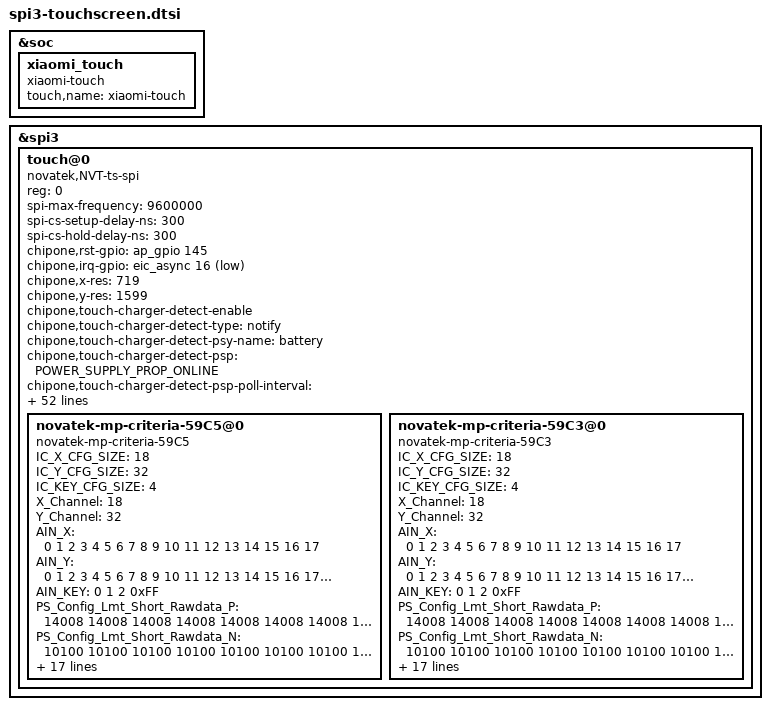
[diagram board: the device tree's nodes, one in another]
/*
 * Copyright (C) 2025 Novatek, Inc.
 *
 * $Revision$
 * $Date$
 *
 * This program is free software; you can redistribute it and/or modify
 * it under the terms of the GNU General Public License as published by
 * the Free Software Foundation; either version 2 of the License, or
 * (at your option) any later version.
 *
 * This program is distributed in the hope that it will be useful, but WITHOUT
 * ANY WARRANTY; without even the implied warranty of MERCHANTABILITY or
 * FITNESS FOR A PARTICULAR PURPOSE.  See the GNU General Public License for
 * more details.
 *
 */

&soc {
    xiaomi_touch {
        status = "okay";
        compatible = "xiaomi-touch";
        touch,name = "xiaomi-touch";
    };
};

&spi3 {
	status = "ok";

	/* Novatek device tree node */
	touch@0 {
		compatible = "novatek,NVT-ts-spi", "omnivision,tcm-spi", "chipone-tddi";
		reg = <0>; //Same as CS ID
		status = "ok";

		spi-max-frequency = <9600000>;	//4800000,9600000,15000000,19200000
		spi-cs-setup-delay-ns = <300>;
		spi-cs-hold-delay-ns = <300>;

		/* chipone_icnl9916x */
		chipone,rst-gpio = <&ap_gpio 145 0x00>;
		chipone,irq-gpio = <&eic_async 16 0x2001>;
		chipone,x-res = <719>;
		chipone,y-res = <1599>;

		/* Charger detect */
		chipone,touch-charger-detect-enable;
		chipone,touch-charger-detect-type = "notify"; /* notify, poll */
		chipone,touch-charger-detect-psy-name = "battery";
		chipone,touch-charger-detect-psp = "POWER_SUPPLY_PROP_ONLINE";
		chipone,touch-charger-detect-psp-poll-interval = <1000>;

		/* Earjack detect */
		chipone,touch-earjack-detect-enable;
		/* MTK:  /sys/bus/platform/drivers/Accdet_Driver/state,
		Sprd: /sys/kernel/headset/state
		QCOM: None, and disable it */
		chipone,touch-earjack-state-filepath = "/sys/kernel/headset/state";
		chipone,touch-earjack-poll-interval = <1000>;

		/* For tp selftest */
                chipone,test-reset-pin;
                chipone,test-int-pin;
                chipone,test-rawdata;
                chipone,test-rawdata-frames      = <1>;
                chipone,rawdata-min              = <1110>;
                chipone,rawdata-max              = <3010>;
                chipone,test-noise;
                chipone,test-noise-frames        = <50>;
                chipone,noise-max                = <120>;
                chipone,test-open;
                chipone,open-min                 = <1700>;
                chipone,test-short;
                chipone,short-min                = <1800>;
                chipone,test-compensate-cap;
                chipone,compensate-cap-min       = <1>;
                chipone,compensate-cap-max       = <127>;

		/* gesture data test */
		chipone,test-gesture-rawdata;
		chipone,test-gesture-rawdata-frames = <1>;
		chipone,gesture-rawdata-min = <100>;
		chipone,gesture-rawdata-max = <10000>;

		chipone,test-gesture-lp-rawdata;
		chipone,test-gesture-lp-rawdata-frames = <1>;
		chipone,gesture-lp-rawdata-min = <100>;
		chipone,gesture-lp-rawdata-max = <10000>;

		chipone,test-gesture-noise;
		chipone,test-gesture-noise-frames = <50>;
		chipone,gesture-noise-max = <1000>;

		chipone,test-gesture-lp-noise;
		chipone,test-gesture-lp-noise-frames = <50>;
		chipone,gesture-lp-noise-max = <1000>;

		/* td4160 */
		omnivision,bus-reg-name = "vdd";
		omnivision,pwr-reg-name = "avdd";
		omnivision,irq-on-state = <0>;
		omnivision,irq-gpio = <&eic_async 16 0x2001>;  /* IRQF_ONESHOT | IRQF_TRIGGER_LOW */
		omnivision,reset-gpio = <&ap_gpio 145 0x00>;
		omnivision,reset-on-state = <0>;
		omnivision,reset-active-ms = <20>;
		omnivision,reset-delay-ms = <200>;
		omnivision,power-delay-ms = <200>;
		omnivision,spi-mode = <3>;
		omnivision,byte-delay-us = <0>;
		omnivision,block-delay-us = <0>;
		omnivision,ubl-max-freq = <3000000>;
		omnivision,ubl-byte-delay-us = <20>;

		/* nt36528a */
		novatek,reset-gpio = <&ap_gpio 145 0x00>;
		novatek,irq-gpio = <&eic_async 16 0x2001>;

		//novatek,pen-support;
		//novatek,spi-rd-fast-addr = <0x03F310>;
		/* MP */
		novatek,mp-support-dt;

		/* for Xiaomi P25A NT36528A TM 6.9" panel module */
		novatek-mp-criteria-59C5@0 {
			#address-cells = <1>;
			#size-cells = <0>;
			compatible = "novatek-mp-criteria-59C5";

			/* MP Config */
			IC_X_CFG_SIZE = <18>;
			IC_Y_CFG_SIZE = <32>;
			IC_KEY_CFG_SIZE = <4>;
			X_Channel = <18>;
			Y_Channel = <32>;
			AIN_X = <0 1 2 3 4 5 6 7 8 9 10 11 12 13 14 15 16 17>;
			AIN_Y = <0 1 2 3 4 5 6 7 8 9 10 11 12 13 14 15 16 17 18 19 20 21 22 23 24 25 26 27 28 29 30 31>;
			AIN_KEY = <0 1 2 0xFF>;

			/* MP Criteria */
			PS_Config_Lmt_Short_Rawdata_P = <
				14008 14008 14008 14008 14008 14008 14008 14008 14008 14008 14008 14008 14008 14008 14008 14008 14008 14008
				14008 14008 14008 14008 14008 14008 14008 14008 14008 14008 14008 14008 14008 14008 14008 14008 14008 14008
				14008 14008 14008 14008 14008 14008 14008 14008 14008 14008 14008 14008 14008 14008 14008 14008 14008 14008
				14008 14008 14008 14008 14008 14008 14008 14008 14008 14008 14008 14008 14008 14008 14008 14008 14008 14008
				14008 14008 14008 14008 14008 14008 14008 14008 14008 14008 14008 14008 14008 14008 14008 14008 14008 14008
				14008 14008 14008 14008 14008 14008 14008 14008 14008 14008 14008 14008 14008 14008 14008 14008 14008 14008
				14008 14008 14008 14008 14008 14008 14008 14008 14008 14008 14008 14008 14008 14008 14008 14008 14008 14008
				14008 14008 14008 14008 14008 14008 14008 14008 14008 14008 14008 14008 14008 14008 14008 14008 14008 14008
				14008 14008 14008 14008 14008 14008 14008 14008 14008 14008 14008 14008 14008 14008 14008 14008 14008 14008
				14008 14008 14008 14008 14008 14008 14008 14008 14008 14008 14008 14008 14008 14008 14008 14008 14008 14008
				14008 14008 14008 14008 14008 14008 14008 14008 14008 14008 14008 14008 14008 14008 14008 14008 14008 14008
				14008 14008 14008 14008 14008 14008 14008 14008 14008 14008 14008 14008 14008 14008 14008 14008 14008 14008
				14008 14008 14008 14008 14008 14008 14008 14008 14008 14008 14008 14008 14008 14008 14008 14008 14008 14008
				14008 14008 14008 14008 14008 14008 14008 14008 14008 14008 14008 14008 14008 14008 14008 14008 14008 14008
				14008 14008 14008 14008 14008 14008 14008 14008 14008 14008 14008 14008 14008 14008 14008 14008 14008 14008
				14008 14008 14008 14008 14008 14008 14008 14008 14008 14008 14008 14008 14008 14008 14008 14008 14008 14008
				14008 14008 14008 14008 14008 14008 14008 14008 14008 14008 14008 14008 14008 14008 14008 14008 14008 14008
				14008 14008 14008 14008 14008 14008 14008 14008 14008 14008 14008 14008 14008 14008 14008 14008 14008 14008
				14008 14008 14008 14008 14008 14008 14008 14008 14008 14008 14008 14008 14008 14008 14008 14008 14008 14008
				14008 14008 14008 14008 14008 14008 14008 14008 14008 14008 14008 14008 14008 14008 14008 14008 14008 14008
				14008 14008 14008 14008 14008 14008 14008 14008 14008 14008 14008 14008 14008 14008 14008 14008 14008 14008
				14008 14008 14008 14008 14008 14008 14008 14008 14008 14008 14008 14008 14008 14008 14008 14008 14008 14008
				14008 14008 14008 14008 14008 14008 14008 14008 14008 14008 14008 14008 14008 14008 14008 14008 14008 14008
				14008 14008 14008 14008 14008 14008 14008 14008 14008 14008 14008 14008 14008 14008 14008 14008 14008 14008
				14008 14008 14008 14008 14008 14008 14008 14008 14008 14008 14008 14008 14008 14008 14008 14008 14008 14008
				14008 14008 14008 14008 14008 14008 14008 14008 14008 14008 14008 14008 14008 14008 14008 14008 14008 14008
				14008 14008 14008 14008 14008 14008 14008 14008 14008 14008 14008 14008 14008 14008 14008 14008 14008 14008
				14008 14008 14008 14008 14008 14008 14008 14008 14008 14008 14008 14008 14008 14008 14008 14008 14008 14008
				14008 14008 14008 14008 14008 14008 14008 14008 14008 14008 14008 14008 14008 14008 14008 14008 14008 14008
				14008 14008 14008 14008 14008 14008 14008 14008 14008 14008 14008 14008 14008 14008 14008 14008 14008 14008
				14008 14008 14008 14008 14008 14008 14008 14008 14008 14008 14008 14008 14008 14008 14008 14008 14008 14008
				14008 14008 14008 14008 14008 14008 14008 14008 14008 14008 14008 14008 14008 14008 14008 14008 14008 14008
				14008 14008 14008>;

			PS_Config_Lmt_Short_Rawdata_N = <
				10100 10100 10100 10100 10100 10100 10100 10100 10100 10100 10100 10100 10100 10100 10100 10100 10100 10100
				10100 10100 10100 10100 10100 10100 10100 10100 10100 10100 10100 10100 10100 10100 10100 10100 10100 10100
				10100 10100 10100 10100 10100 10100 10100 10100 10100 10100 10100 10100 10100 10100 10100 10100 10100 10100
				10100 10100 10100 10100 10100 10100 10100 10100 10100 10100 10100 10100 10100 10100 10100 10100 10100 10100
				10100 10100 10100 10100 10100 10100 10100 10100 10100 10100 10100 10100 10100 10100 10100 10100 10100 10100
				10100 10100 10100 10100 10100 10100 10100 10100 10100 10100 10100 10100 10100 10100 10100 10100 10100 10100
				10100 10100 10100 10100 10100 10100 10100 10100 10100 10100 10100 10100 10100 10100 10100 10100 10100 10100
				10100 10100 10100 10100 10100 10100 10100 10100 10100 10100 10100 10100 10100 10100 10100 10100 10100 10100
				10100 10100 10100 10100 10100 10100 10100 10100 10100 10100 10100 10100 10100 10100 10100 10100 10100 10100
				10100 10100 10100 10100 10100 10100 10100 10100 10100 10100 10100 10100 10100 10100 10100 10100 10100 10100
				10100 10100 10100 10100 10100 10100 10100 10100 10100 10100 10100 10100 10100 10100 10100 10100 10100 10100
				10100 10100 10100 10100 10100 10100 10100 10100 10100 10100 10100 10100 10100 10100 10100 10100 10100 10100
				10100 10100 10100 10100 10100 10100 10100 10100 10100 10100 10100 10100 10100 10100 10100 10100 10100 10100
				10100 10100 10100 10100 10100 10100 10100 10100 10100 10100 10100 10100 10100 10100 10100 10100 10100 10100
				10100 10100 10100 10100 10100 10100 10100 10100 10100 10100 10100 10100 10100 10100 10100 10100 10100 10100
				10100 10100 10100 10100 10100 10100 10100 10100 10100 10100 10100 10100 10100 10100 10100 10100 10100 10100
				10100 10100 10100 10100 10100 10100 10100 10100 10100 10100 10100 10100 10100 10100 10100 10100 10100 10100
				10100 10100 10100 10100 10100 10100 10100 10100 10100 10100 10100 10100 10100 10100 10100 10100 10100 10100
				10100 10100 10100 10100 10100 10100 10100 10100 10100 10100 10100 10100 10100 10100 10100 10100 10100 10100
				10100 10100 10100 10100 10100 10100 10100 10100 10100 10100 10100 10100 10100 10100 10100 10100 10100 10100
				10100 10100 10100 10100 10100 10100 10100 10100 10100 10100 10100 10100 10100 10100 10100 10100 10100 10100
				10100 10100 10100 10100 10100 10100 10100 10100 10100 10100 10100 10100 10100 10100 10100 10100 10100 10100
				10100 10100 10100 10100 10100 10100 10100 10100 10100 10100 10100 10100 10100 10100 10100 10100 10100 10100
				10100 10100 10100 10100 10100 10100 10100 10100 10100 10100 10100 10100 10100 10100 10100 10100 10100 10100
				10100 10100 10100 10100 10100 10100 10100 10100 10100 10100 10100 10100 10100 10100 10100 10100 10100 10100
				10100 10100 10100 10100 10100 10100 10100 10100 10100 10100 10100 10100 10100 10100 10100 10100 10100 10100
				10100 10100 10100 10100 10100 10100 10100 10100 10100 10100 10100 10100 10100 10100 10100 10100 10100 10100
				10100 10100 10100 10100 10100 10100 10100 10100 10100 10100 10100 10100 10100 10100 10100 10100 10100 10100
				10100 10100 10100 10100 10100 10100 10100 10100 10100 10100 10100 10100 10100 10100 10100 10100 10100 10100
				10100 10100 10100 10100 10100 10100 10100 10100 10100 10100 10100 10100 10100 10100 10100 10100 10100 10100
				10100 10100 10100 10100 10100 10100 10100 10100 10100 10100 10100 10100 10100 10100 10100 10100 10100 10100
				10100 10100 10100 10100 10100 10100 10100 10100 10100 10100 10100 10100 10100 10100 10100 10100 10100 10100
				10100 10100 10100>;

			PS_Config_Lmt_Open_Rawdata_P = <
				65535 3126 3087 3034 2962 2897 2852 2744 65535 65535 2729 2814 2859 2899 2937 2974 3006 65535
				3247 3228 3191 3153 3083 3013 2958 2901 2848 2748 2786 2827 2874 2922 2967 2988 3018 3091
				3289 3293 3238 3181 3112 3044 2986 2932 2887 2801 2834 2881 2925 2975 3021 3056 3102 3161
				3219 3240 3185 3123 3053 2986 2926 2874 2827 2792 2828 2870 2918 2968 3016 3055 3104 3163
				3329 3360 3304 3242 3175 3105 3042 2993 2943 2818 2848 2895 2941 2996 3041 3079 3128 3178
				3349 3388 3333 3270 3199 3130 3074 3020 2975 2845 2877 2925 2972 3024 3072 3109 3161 3214
				3303 3269 3199 3150 3074 3003 2958 2898 2846 2947 2993 3048 3084 3137 3191 3221 3287 3209
				3350 3310 3245 3191 3114 3044 2997 2941 2885 2957 3004 3051 3090 3146 3198 3230 3289 3228
				3413 3368 3303 3249 3175 3105 3056 2999 2943 2988 3032 3084 3118 3177 3231 3262 3324 3277
				3468 3420 3357 3298 3221 3150 3102 3044 2988 3003 3049 3101 3136 3192 3245 3280 3338 3304
				3499 3448 3380 3326 3248 3174 3129 3072 3016 3156 3203 3252 3297 3354 3405 3438 3501 3473
				3534 3475 3409 3354 3276 3203 3154 3090 3038 3137 3182 3235 3279 3336 3389 3427 3487 3476
				3588 3532 3466 3413 3333 3256 3210 3146 3093 3135 3186 3231 3276 3336 3385 3420 3482 3483
				3661 3606 3534 3479 3402 3326 3275 3214 3160 3182 3233 3279 3325 3384 3431 3466 3528 3535
				3703 3644 3577 3522 3451 3374 3322 3262 3207 3273 3317 3373 3412 3475 3527 3556 3619 3644
				3758 3696 3630 3569 3489 3416 3363 3304 3245 3242 3286 3340 3384 3441 3496 3534 3595 3630
				3795 3732 3668 3606 3529 3454 3401 3340 3283 3328 3370 3422 3468 3528 3583 3615 3674 3721
				3833 3766 3707 3643 3563 3489 3438 3373 3318 3336 3377 3436 3473 3534 3585 3620 3674 3721
				3872 3809 3748 3689 3606 3529 3482 3413 3366 3371 3419 3462 3514 3569 3620 3664 3718 3769
				3907 3840 3776 3717 3634 3559 3501 3440 3385 3402 3447 3494 3545 3599 3654 3697 3751 3814
				4015 3949 3884 3825 3742 3662 3609 3546 3493 3431 3480 3531 3578 3633 3689 3725 3781 3849
				4057 3993 3933 3868 3791 3711 3657 3594 3534 3543 3592 3644 3695 3753 3807 3850 3902 3962
				4092 4021 3963 3902 3826 3752 3693 3634 3569 3613 3660 3714 3762 3821 3877 3913 3965 4031
				4122 4053 3996 3927 3849 3773 3714 3654 3597 3599 3644 3699 3746 3804 3863 3906 3961 4021
				4236 4161 4106 4043 3959 3881 3830 3770 3709 3723 3769 3821 3868 3928 3979 4022 4074 4140
				4224 4157 4103 4038 3954 3879 3825 3763 3707 3749 3795 3850 3898 3961 4015 4063 4112 4173
				4281 4222 4162 4101 4022 3944 3886 3822 3765 3774 3828 3877 3928 3984 4042 4087 4140 4204
				4336 4274 4217 4157 4071 4003 3944 3881 3823 3833 3878 3931 3983 4038 4095 4136 4185 4250
				3871 4334 4273 4213 4133 4054 3994 3931 3872 3865 3916 3970 4019 4084 4141 4183 4236 3815
				3924 4407 4350 4278 4203 4124 4061 3994 3941 3884 3927 3979 4029 4085 4138 4186 4236 3802
				3991 4577 4515 4444 4361 4278 4214 4154 4098 3987 4033 4085 4140 4203 4260 4311 4365 3840
				4017 4263 4536 4473 4383 4301 4239 4172 4116 3994 4045 4098 4150 4213 4274 4316 4066 3868
				5120 5120 5120>;

			PS_Config_Lmt_Open_Rawdata_N = <
				(-65535) 1340 1323 1300 1270 1241 1222 1176 (-65535) (-65535) 1169 1206 1225 1243 1259 1274 1288 (-65535)
				1391 1384 1367 1351 1321 1291 1268 1243 1220 1178 1194 1211 1232 1252 1271 1280 1294 1325
				1409 1411 1388 1363 1334 1304 1280 1256 1237 1201 1214 1235 1253 1275 1295 1310 1330 1355
				1379 1388 1365 1339 1309 1280 1254 1232 1211 1196 1212 1230 1250 1272 1292 1309 1330 1355
				1427 1440 1416 1390 1361 1331 1304 1283 1261 1208 1220 1241 1261 1284 1303 1319 1340 1362
				1435 1452 1429 1402 1371 1342 1318 1294 1275 1219 1233 1253 1274 1296 1316 1333 1355 1378
				1415 1401 1371 1350 1318 1287 1268 1242 1220 1263 1283 1306 1322 1345 1367 1381 1409 1375
				1436 1418 1391 1367 1334 1304 1285 1261 1237 1267 1288 1307 1324 1348 1370 1384 1409 1384
				1463 1444 1415 1393 1361 1331 1310 1285 1261 1280 1300 1322 1336 1361 1385 1398 1424 1405
				1486 1466 1439 1414 1381 1350 1330 1304 1280 1287 1307 1329 1344 1368 1391 1406 1430 1416
				1499 1478 1448 1426 1392 1360 1341 1316 1292 1352 1373 1394 1413 1438 1459 1474 1501 1489
				1514 1489 1461 1438 1404 1373 1352 1324 1302 1345 1364 1387 1405 1430 1453 1469 1495 1490
				1538 1514 1486 1463 1429 1396 1376 1348 1325 1343 1366 1385 1404 1430 1451 1466 1492 1493
				1569 1546 1514 1491 1458 1426 1403 1378 1354 1364 1385 1405 1425 1450 1471 1486 1512 1515
				1587 1562 1533 1510 1479 1446 1424 1398 1375 1403 1421 1445 1462 1489 1511 1524 1551 1562
				1610 1584 1556 1529 1495 1464 1441 1416 1391 1390 1408 1432 1450 1475 1498 1514 1541 1556
				1627 1600 1572 1546 1513 1480 1457 1432 1407 1426 1444 1466 1486 1512 1535 1549 1574 1595
				1643 1614 1589 1561 1527 1495 1474 1445 1422 1430 1447 1472 1489 1514 1537 1552 1574 1595
				1660 1633 1606 1581 1546 1513 1492 1463 1442 1445 1465 1484 1506 1529 1552 1570 1594 1615
				1675 1646 1618 1593 1558 1525 1501 1474 1451 1458 1477 1498 1519 1543 1566 1585 1607 1634
				1721 1693 1664 1639 1604 1570 1547 1520 1497 1471 1492 1513 1534 1557 1581 1597 1621 1649
				1739 1711 1685 1658 1625 1591 1567 1540 1514 1519 1540 1562 1583 1609 1631 1650 1672 1698
				1754 1723 1699 1672 1640 1608 1583 1558 1529 1549 1568 1592 1612 1637 1661 1677 1699 1727
				1766 1737 1712 1683 1649 1617 1592 1566 1541 1543 1562 1585 1606 1630 1655 1674 1697 1723
				1816 1783 1760 1733 1697 1663 1642 1616 1589 1595 1615 1637 1658 1684 1705 1724 1746 1774
				1810 1781 1759 1730 1694 1663 1639 1613 1589 1607 1627 1650 1670 1697 1721 1741 1762 1789
				1835 1810 1784 1757 1724 1690 1666 1638 1613 1618 1640 1661 1684 1708 1732 1751 1774 1802
				1858 1832 1807 1781 1745 1715 1690 1663 1639 1643 1662 1685 1707 1730 1755 1772 1793 1822
				1659 1858 1831 1805 1771 1738 1712 1685 1660 1657 1678 1702 1723 1750 1775 1793 1816 1635
				1682 1889 1864 1834 1801 1768 1741 1712 1689 1664 1683 1705 1727 1751 1774 1794 1816 1630
				1711 1961 1935 1904 1869 1834 1806 1780 1756 1709 1729 1751 1774 1801 1826 1847 1871 1646
				1721 1827 1944 1917 1879 1843 1817 1788 1764 1712 1733 1756 1778 1805 1832 1850 1742 1658
				(-511) (-511) (-511)>;

			PS_Config_Lmt_FW_Rawdata_P = <
				65535 1152 1130 1123 1124 1141 1088 1120 65535 65535 1098 1113 1127 1120 1106 1102 1117 65535
				1119 1114 1106 1109 1107 1131 1110 1116 1123 1123 1140 1086 1128 1109 1106 1121 1119 1116
				1119 1116 1117 1105 1127 1126 1105 1128 1103 1110 1106 1131 1093 1140 1107 1098 1130 1124
				1098 1134 1116 1098 1140 1107 1134 1113 1088 1144 1100 1126 1110 1089 1133 1133 1113 1102
				1089 1138 1116 1091 1131 1138 1110 1121 1114 1128 1130 1106 1123 1120 1107 1113 1147 1117
				1133 1117 1133 1131 1110 1102 1117 1116 1144 1128 1128 1110 1110 1109 1124 1127 1124 1100
				1109 1120 1103 1113 1154 1102 1089 1151 1086 1106 1096 1112 1145 1085 1134 1142 1137 1088
				1120 1127 1110 1113 1116 1117 1099 1123 1114 1110 1120 1120 1119 1091 1123 1116 1142 1099
				1110 1142 1117 1138 1100 1135 1119 1084 1137 1095 1148 1070 1113 1145 1082 1120 1086 1137
				1114 1113 1124 1138 1119 1112 1130 1114 1114 1112 1113 1106 1124 1128 1093 1126 1074 1137
				1107 1112 1102 1103 1117 1120 1119 1098 1106 1119 1110 1116 1130 1103 1114 1117 1126 1117
				1113 1144 1112 1124 1102 1127 1121 1112 1126 1123 1096 1131 1126 1121 1120 1123 1133 1119
				1107 1127 1113 1131 1130 1106 1086 1123 1119 1092 1141 1121 1093 1124 1124 1114 1116 1128
				1116 1152 1119 1138 1121 1114 1123 1126 1127 1113 1126 1116 1105 1128 1151 1091 1134 1107
				1054 1121 1140 1128 1103 1086 1117 1149 1106 1147 1085 1098 1131 1145 1100 1123 1131 1112
				1105 1135 1112 1131 1138 1113 1086 1137 1116 1127 1144 1106 1114 1112 1126 1137 1113 1119
				1169 1065 1131 1077 1147 1121 1078 1135 1127 1119 1123 1113 1106 1106 1140 1105 1102 1105
				1116 1116 1112 1121 1123 1117 1109 1119 1113 1133 1113 1116 1137 1114 1123 1127 1113 1123
				1121 1127 1123 1092 1135 1140 1119 1110 1140 1120 1107 1107 1131 1126 1116 1106 1121 1106
				1099 1134 1100 1098 1142 1138 1106 1095 1151 1109 1134 1137 1114 1099 1110 1126 1126 1120
				1107 1113 1114 1126 1128 1121 1109 1123 1137 1138 1116 1114 1134 1098 1113 1123 1102 1133
				1126 1135 1130 1102 1107 1138 1130 1106 1119 1105 1152 1120 1099 1099 1133 1147 1098 1127
				1096 1144 1119 1099 1099 1142 1116 1114 1095 1121 1130 1113 1102 1128 1124 1123 1093 1112
				1142 1130 1151 1117 1096 1107 1142 1137 1098 1134 1114 1133 1106 1113 1123 1145 1106 1155
				1098 1144 1112 1098 1103 1141 1140 1120 1092 1117 1114 1109 1113 1138 1134 1095 1098 1119
				1110 1128 1140 1112 1075 1110 1163 1133 1110 1112 1105 1105 1124 1145 1105 1114 1135 1109
				1082 1119 1063 1078 1126 1141 1133 1103 1110 1126 1119 1103 1113 1138 1110 1100 1114 1105
				1117 1114 1107 1112 1128 1120 1121 1112 1116 1127 1144 1135 1092 1079 1123 1127 1144 1120
				1135 1103 1130 1121 1127 1119 1110 1089 1093 1144 1133 1110 1107 1105 1126 1128 1126 1098
				1117 1113 1121 1124 1102 1102 1099 1100 1100 1107 1112 1124 1131 1124 1107 1103 1103 1110
				1141 1114 1130 1137 1121 1112 1091 1081 1086 1137 1141 1106 1100 1095 1123 1126 1137 1127
				1102 1137 1093 1095 1106 1114 1135 1105 1121 1116 1112 1137 1149 1142 1130 1121 1110 1120
				3840 3840 3840>;

			PS_Config_Lmt_FW_Rawdata_N = <
				(-65535) 494 484 481 482 489 466 480 (-65535) (-65535) 470 477 483 480 474 472 479 (-65535)
				479 478 474 475 475 485 476 478 481 481 488 466 484 475 474 481 479 478
				479 478 479 473 483 482 473 484 473 476 474 485 469 488 475 470 484 482
				470 486 478 470 488 475 486 477 466 490 472 482 476 467 485 485 477 472
				467 488 478 467 485 488 476 481 478 484 484 474 481 480 475 477 491 479
				485 479 485 485 476 472 479 478 490 484 484 476 476 475 482 483 482 472
				475 480 473 477 494 472 467 493 466 474 470 476 491 465 486 490 487 466
				480 483 476 477 478 479 471 481 478 476 480 480 479 467 481 478 490 471
				476 490 479 488 472 487 479 464 487 469 492 458 477 491 464 480 466 487
				478 477 482 488 479 476 484 478 478 476 477 474 482 484 469 482 460 487
				475 476 472 473 479 480 479 470 474 479 476 478 484 473 478 479 482 479
				477 490 476 482 472 483 481 476 482 481 470 485 482 481 480 481 485 479
				475 483 477 485 484 474 466 481 479 468 489 481 469 482 482 478 478 484
				478 494 479 488 481 478 481 482 483 477 482 478 473 484 493 467 486 475
				452 481 488 484 473 466 479 493 474 491 465 470 485 491 472 481 485 476
				473 487 476 485 488 477 466 487 478 483 490 474 478 476 482 487 477 479
				501 457 485 461 491 481 462 487 483 479 481 477 474 474 488 473 472 473
				478 478 476 481 481 479 475 479 477 485 477 478 487 478 481 483 477 481
				481 483 481 468 487 488 479 476 488 480 475 475 485 482 478 474 481 474
				471 486 472 470 490 488 474 469 493 475 486 487 478 471 476 482 482 480
				475 477 478 482 484 481 475 481 487 488 478 478 486 470 477 481 472 485
				482 487 484 472 475 488 484 474 479 473 494 480 471 471 485 491 470 483
				470 490 479 471 471 490 478 478 469 481 484 477 472 484 482 481 469 476
				490 484 493 479 470 475 490 487 470 486 478 485 474 477 481 491 474 495
				470 490 476 470 473 489 488 480 468 479 478 475 477 488 486 469 470 479
				476 484 488 476 461 476 499 485 476 476 473 473 482 491 473 478 487 475
				464 479 455 462 482 489 485 473 476 482 479 473 477 488 476 472 478 473
				479 478 475 476 484 480 481 476 478 483 490 487 468 463 481 483 490 480
				487 473 484 481 483 479 476 467 469 490 485 476 475 473 482 484 482 470
				479 477 481 482 472 472 471 472 472 475 476 482 485 482 475 473 473 476
				489 478 484 487 481 476 467 463 466 487 489 474 472 469 481 482 487 483
				472 487 469 469 474 478 487 473 481 478 476 487 493 490 484 481 476 480
				240 240 240>;

			PS_Config_Lmt_FW_CC_P = <
				65535 32 32 32 30 30 30 29 65535 65535 29 29 30 30 32 32 32 65535
				33 32 32 30 30 30 29 29 29 29 29 29 30 30 32 32 32 33
				33 33 32 32 32 30 30 29 29 29 29 29 30 30 32 32 32 33
				33 32 32 32 30 30 30 29 29 29 29 30 30 32 32 32 33 33
				33 33 32 32 32 30 30 30 29 29 30 30 30 32 32 32 33 33
				33 33 32 32 32 32 30 30 30 29 30 30 30 32 32 32 33 34
				34 33 33 32 30 30 30 29 29 29 29 30 30 32 32 33 33 34
				34 33 33 32 32 30 30 29 29 29 30 30 30 32 32 33 33 34
				34 33 33 32 32 30 30 30 29 29 30 30 30 32 32 33 33 34
				34 33 33 32 32 30 30 30 29 29 30 30 30 32 32 33 33 34
				34 34 33 32 32 32 30 30 30 30 30 32 32 32 33 33 34 34
				34 33 33 32 32 30 30 30 29 30 30 30 32 32 32 33 34 34
				34 33 33 32 32 32 32 30 30 30 30 32 32 32 33 33 34 34
				34 33 33 32 32 32 30 30 30 30 30 32 32 32 32 33 33 34
				34 34 33 33 32 32 32 30 30 30 30 32 32 32 33 33 33 34
				34 34 33 33 32 32 32 32 30 30 32 32 32 33 33 33 34 34
				34 34 33 33 33 32 32 32 30 30 32 32 32 33 33 33 34 34
				36 34 33 33 33 32 32 32 30 32 32 32 32 33 33 33 34 34
				36 34 34 33 33 33 33 32 32 32 32 33 33 33 33 34 34 36
				36 34 34 34 33 33 33 32 32 32 32 33 33 33 34 34 34 36
				36 36 34 34 34 33 33 33 32 33 33 33 33 34 34 34 34 36
				36 36 34 34 34 33 33 33 33 33 33 33 34 34 34 34 36 36
				37 36 36 36 36 34 34 34 34 33 34 34 34 34 36 36 36 37
				36 36 36 34 34 34 34 33 33 33 34 34 34 34 36 36 36 37
				37 36 36 36 36 34 34 34 34 34 34 34 34 36 36 36 36 37
				37 36 36 36 36 34 34 34 34 34 34 34 34 34 36 36 36 37
				37 37 37 36 36 36 36 36 34 34 34 36 36 36 36 36 37 37
				37 37 36 36 36 36 36 34 34 34 34 36 36 36 36 36 37 37
				39 37 37 37 37 36 36 36 36 36 36 36 36 36 36 36 37 39
				39 37 37 37 37 36 36 36 36 36 36 36 36 36 37 37 37 39
				39 37 37 37 36 36 36 36 36 36 36 36 36 36 37 37 37 39
				39 37 37 37 37 37 36 36 36 36 36 36 36 36 36 37 37 39
				314 314 314>;

			PS_Config_Lmt_FW_CC_N = <
				(-65535) 14 14 14 14 14 14 13 (-65535) (-65535) 13 13 14 14 14 14 14 (-65535)
				15 14 14 14 14 14 13 13 13 13 13 13 14 14 14 14 14 15
				15 15 14 14 14 14 14 13 13 13 13 13 14 14 14 14 14 15
				15 14 14 14 14 14 14 13 13 13 13 14 14 14 14 14 15 15
				15 15 14 14 14 14 14 14 13 13 14 14 14 14 14 14 15 15
				15 15 14 14 14 14 14 14 14 13 14 14 14 14 14 14 15 16
				16 15 15 14 14 14 14 13 13 13 13 14 14 14 14 15 15 16
				16 15 15 14 14 14 14 13 13 13 14 14 14 14 14 15 15 16
				16 15 15 14 14 14 14 14 13 13 14 14 14 14 14 15 15 16
				16 15 15 14 14 14 14 14 13 13 14 14 14 14 14 15 15 16
				16 16 15 14 14 14 14 14 14 14 14 14 14 14 15 15 16 16
				16 15 15 14 14 14 14 14 13 14 14 14 14 14 14 15 16 16
				16 15 15 14 14 14 14 14 14 14 14 14 14 14 15 15 16 16
				16 15 15 14 14 14 14 14 14 14 14 14 14 14 14 15 15 16
				16 16 15 15 14 14 14 14 14 14 14 14 14 14 15 15 15 16
				16 16 15 15 14 14 14 14 14 14 14 14 14 15 15 15 16 16
				16 16 15 15 15 14 14 14 14 14 14 14 14 15 15 15 16 16
				16 16 15 15 15 14 14 14 14 14 14 14 14 15 15 15 16 16
				16 16 16 15 15 15 15 14 14 14 14 15 15 15 15 16 16 16
				16 16 16 16 15 15 15 14 14 14 14 15 15 15 16 16 16 16
				16 16 16 16 16 15 15 15 14 15 15 15 15 16 16 16 16 16
				16 16 16 16 16 15 15 15 15 15 15 15 16 16 16 16 16 16
				17 16 16 16 16 16 16 16 16 15 16 16 16 16 16 16 16 17
				16 16 16 16 16 16 16 15 15 15 16 16 16 16 16 16 16 17
				17 16 16 16 16 16 16 16 16 16 16 16 16 16 16 16 16 17
				17 16 16 16 16 16 16 16 16 16 16 16 16 16 16 16 16 17
				17 17 17 16 16 16 16 16 16 16 16 16 16 16 16 16 17 17
				17 17 16 16 16 16 16 16 16 16 16 16 16 16 16 16 17 17
				17 17 17 17 17 16 16 16 16 16 16 16 16 16 16 16 17 17
				17 17 17 17 17 16 16 16 16 16 16 16 16 16 17 17 17 17
				17 17 17 17 16 16 16 16 16 16 16 16 16 16 17 17 17 17
				17 17 17 17 17 17 16 16 16 16 16 16 16 16 16 17 17 17
				0 0 0>;

			PS_Config_Lmt_FW_Diff_P = <
				65535 50 50 50 50 50 50 50 65535 65535 50 50 50 50 50 50 50 65535
				50 50 50 50 50 50 50 50 50 50 50 50 50 50 50 50 50 50
				50 50 50 50 50 50 50 50 50 50 50 50 50 50 50 50 50 50
				50 50 50 50 50 50 50 50 50 50 50 50 50 50 50 50 50 50
				50 50 50 50 50 50 50 50 50 50 50 50 50 50 50 50 50 50
				50 50 50 50 50 50 50 50 50 50 50 50 50 50 50 50 50 50
				50 50 50 50 50 50 50 50 50 50 50 50 50 50 50 50 50 50
				50 50 50 50 50 50 50 50 50 50 50 50 50 50 50 50 50 50
				50 50 50 50 50 50 50 50 50 50 50 50 50 50 50 50 50 50
				50 50 50 50 50 50 50 50 50 50 50 50 50 50 50 50 50 50
				50 50 50 50 50 50 50 50 50 50 50 50 50 50 50 50 50 50
				50 50 50 50 50 50 50 50 50 50 50 50 50 50 50 50 50 50
				50 50 50 50 50 50 50 50 50 50 50 50 50 50 50 50 50 50
				50 50 50 50 50 50 50 50 50 50 50 50 50 50 50 50 50 50
				50 50 50 50 50 50 50 50 50 50 50 50 50 50 50 50 50 50
				50 50 50 50 50 50 50 50 50 50 50 50 50 50 50 50 50 50
				50 50 50 50 50 50 50 50 50 50 50 50 50 50 50 50 50 50
				50 50 50 50 50 50 50 50 50 50 50 50 50 50 50 50 50 50
				50 50 50 50 50 50 50 50 50 50 50 50 50 50 50 50 50 50
				50 50 50 50 50 50 50 50 50 50 50 50 50 50 50 50 50 50
				50 50 50 50 50 50 50 50 50 50 50 50 50 50 50 50 50 50
				50 50 50 50 50 50 50 50 50 50 50 50 50 50 50 50 50 50
				50 50 50 50 50 50 50 50 50 50 50 50 50 50 50 50 50 50
				50 50 50 50 50 50 50 50 50 50 50 50 50 50 50 50 50 50
				50 50 50 50 50 50 50 50 50 50 50 50 50 50 50 50 50 50
				50 50 50 50 50 50 50 50 50 50 50 50 50 50 50 50 50 50
				50 50 50 50 50 50 50 50 50 50 50 50 50 50 50 50 50 50
				50 50 50 50 50 50 50 50 50 50 50 50 50 50 50 50 50 50
				50 50 50 50 50 50 50 50 50 50 50 50 50 50 50 50 50 50
				50 50 50 50 50 50 50 50 50 50 50 50 50 50 50 50 50 50
				50 50 50 50 50 50 50 50 50 50 50 50 50 50 50 50 50 50
				50 50 50 50 50 50 50 50 50 50 50 50 50 50 50 50 50 50
				75 75 75>;

			PS_Config_Lmt_FW_Diff_N = <
				(-65535) (-50) (-50) (-50) (-50) (-50) (-50) (-50) (-65535) (-65535) (-50) (-50) (-50) (-50) (-50) (-50) (-50) (-65535)
				(-50) (-50) (-50) (-50) (-50) (-50) (-50) (-50) (-50) (-50) (-50) (-50) (-50) (-50) (-50) (-50) (-50) (-50)
				(-50) (-50) (-50) (-50) (-50) (-50) (-50) (-50) (-50) (-50) (-50) (-50) (-50) (-50) (-50) (-50) (-50) (-50)
				(-50) (-50) (-50) (-50) (-50) (-50) (-50) (-50) (-50) (-50) (-50) (-50) (-50) (-50) (-50) (-50) (-50) (-50)
				(-50) (-50) (-50) (-50) (-50) (-50) (-50) (-50) (-50) (-50) (-50) (-50) (-50) (-50) (-50) (-50) (-50) (-50)
				(-50) (-50) (-50) (-50) (-50) (-50) (-50) (-50) (-50) (-50) (-50) (-50) (-50) (-50) (-50) (-50) (-50) (-50)
				(-50) (-50) (-50) (-50) (-50) (-50) (-50) (-50) (-50) (-50) (-50) (-50) (-50) (-50) (-50) (-50) (-50) (-50)
				(-50) (-50) (-50) (-50) (-50) (-50) (-50) (-50) (-50) (-50) (-50) (-50) (-50) (-50) (-50) (-50) (-50) (-50)
				(-50) (-50) (-50) (-50) (-50) (-50) (-50) (-50) (-50) (-50) (-50) (-50) (-50) (-50) (-50) (-50) (-50) (-50)
				(-50) (-50) (-50) (-50) (-50) (-50) (-50) (-50) (-50) (-50) (-50) (-50) (-50) (-50) (-50) (-50) (-50) (-50)
				(-50) (-50) (-50) (-50) (-50) (-50) (-50) (-50) (-50) (-50) (-50) (-50) (-50) (-50) (-50) (-50) (-50) (-50)
				(-50) (-50) (-50) (-50) (-50) (-50) (-50) (-50) (-50) (-50) (-50) (-50) (-50) (-50) (-50) (-50) (-50) (-50)
				(-50) (-50) (-50) (-50) (-50) (-50) (-50) (-50) (-50) (-50) (-50) (-50) (-50) (-50) (-50) (-50) (-50) (-50)
				(-50) (-50) (-50) (-50) (-50) (-50) (-50) (-50) (-50) (-50) (-50) (-50) (-50) (-50) (-50) (-50) (-50) (-50)
				(-50) (-50) (-50) (-50) (-50) (-50) (-50) (-50) (-50) (-50) (-50) (-50) (-50) (-50) (-50) (-50) (-50) (-50)
				(-50) (-50) (-50) (-50) (-50) (-50) (-50) (-50) (-50) (-50) (-50) (-50) (-50) (-50) (-50) (-50) (-50) (-50)
				(-50) (-50) (-50) (-50) (-50) (-50) (-50) (-50) (-50) (-50) (-50) (-50) (-50) (-50) (-50) (-50) (-50) (-50)
				(-50) (-50) (-50) (-50) (-50) (-50) (-50) (-50) (-50) (-50) (-50) (-50) (-50) (-50) (-50) (-50) (-50) (-50)
				(-50) (-50) (-50) (-50) (-50) (-50) (-50) (-50) (-50) (-50) (-50) (-50) (-50) (-50) (-50) (-50) (-50) (-50)
				(-50) (-50) (-50) (-50) (-50) (-50) (-50) (-50) (-50) (-50) (-50) (-50) (-50) (-50) (-50) (-50) (-50) (-50)
				(-50) (-50) (-50) (-50) (-50) (-50) (-50) (-50) (-50) (-50) (-50) (-50) (-50) (-50) (-50) (-50) (-50) (-50)
				(-50) (-50) (-50) (-50) (-50) (-50) (-50) (-50) (-50) (-50) (-50) (-50) (-50) (-50) (-50) (-50) (-50) (-50)
				(-50) (-50) (-50) (-50) (-50) (-50) (-50) (-50) (-50) (-50) (-50) (-50) (-50) (-50) (-50) (-50) (-50) (-50)
				(-50) (-50) (-50) (-50) (-50) (-50) (-50) (-50) (-50) (-50) (-50) (-50) (-50) (-50) (-50) (-50) (-50) (-50)
				(-50) (-50) (-50) (-50) (-50) (-50) (-50) (-50) (-50) (-50) (-50) (-50) (-50) (-50) (-50) (-50) (-50) (-50)
				(-50) (-50) (-50) (-50) (-50) (-50) (-50) (-50) (-50) (-50) (-50) (-50) (-50) (-50) (-50) (-50) (-50) (-50)
				(-50) (-50) (-50) (-50) (-50) (-50) (-50) (-50) (-50) (-50) (-50) (-50) (-50) (-50) (-50) (-50) (-50) (-50)
				(-50) (-50) (-50) (-50) (-50) (-50) (-50) (-50) (-50) (-50) (-50) (-50) (-50) (-50) (-50) (-50) (-50) (-50)
				(-50) (-50) (-50) (-50) (-50) (-50) (-50) (-50) (-50) (-50) (-50) (-50) (-50) (-50) (-50) (-50) (-50) (-50)
				(-50) (-50) (-50) (-50) (-50) (-50) (-50) (-50) (-50) (-50) (-50) (-50) (-50) (-50) (-50) (-50) (-50) (-50)
				(-50) (-50) (-50) (-50) (-50) (-50) (-50) (-50) (-50) (-50) (-50) (-50) (-50) (-50) (-50) (-50) (-50) (-50)
				(-50) (-50) (-50) (-50) (-50) (-50) (-50) (-50) (-50) (-50) (-50) (-50) (-50) (-50) (-50) (-50) (-50) (-50)
				(-75) (-75) (-75)>;

			PS_Config_Diff_Test_Frame = <50>;
		};

		/* for Xiaomi P25A NT36528A CSOT 6.9" panel module */
		novatek-mp-criteria-59C3@0 {
			#address-cells = <1>;
			#size-cells = <0>;
			compatible = "novatek-mp-criteria-59C3";

			/* MP Config */
			IC_X_CFG_SIZE = <18>;
			IC_Y_CFG_SIZE = <32>;
			IC_KEY_CFG_SIZE = <4>;
			X_Channel = <18>;
			Y_Channel = <32>;
			AIN_X = <0 1 2 3 4 5 6 7 8 9 10 11 12 13 14 15 16 17>;
			AIN_Y = <0 1 2 3 4 5 6 7 8 9 10 11 12 13 14 15 16 17 18 19 20 21 22 23 24 25 26 27 28 29 30 31>;
			AIN_KEY = <0 1 2 0xFF>;

			/* MP Criteria */
			PS_Config_Lmt_Short_Rawdata_P = <
				14008 14008 14008 14008 14008 14008 14008 14008 14008 14008 14008 14008 14008 14008 14008 14008 14008 14008
				14008 14008 14008 14008 14008 14008 14008 14008 14008 14008 14008 14008 14008 14008 14008 14008 14008 14008
				14008 14008 14008 14008 14008 14008 14008 14008 14008 14008 14008 14008 14008 14008 14008 14008 14008 14008
				14008 14008 14008 14008 14008 14008 14008 14008 14008 14008 14008 14008 14008 14008 14008 14008 14008 14008
				14008 14008 14008 14008 14008 14008 14008 14008 14008 14008 14008 14008 14008 14008 14008 14008 14008 14008
				14008 14008 14008 14008 14008 14008 14008 14008 14008 14008 14008 14008 14008 14008 14008 14008 14008 14008
				14008 14008 14008 14008 14008 14008 14008 14008 14008 14008 14008 14008 14008 14008 14008 14008 14008 14008
				14008 14008 14008 14008 14008 14008 14008 14008 14008 14008 14008 14008 14008 14008 14008 14008 14008 14008
				14008 14008 14008 14008 14008 14008 14008 14008 14008 14008 14008 14008 14008 14008 14008 14008 14008 14008
				14008 14008 14008 14008 14008 14008 14008 14008 14008 14008 14008 14008 14008 14008 14008 14008 14008 14008
				14008 14008 14008 14008 14008 14008 14008 14008 14008 14008 14008 14008 14008 14008 14008 14008 14008 14008
				14008 14008 14008 14008 14008 14008 14008 14008 14008 14008 14008 14008 14008 14008 14008 14008 14008 14008
				14008 14008 14008 14008 14008 14008 14008 14008 14008 14008 14008 14008 14008 14008 14008 14008 14008 14008
				14008 14008 14008 14008 14008 14008 14008 14008 14008 14008 14008 14008 14008 14008 14008 14008 14008 14008
				14008 14008 14008 14008 14008 14008 14008 14008 14008 14008 14008 14008 14008 14008 14008 14008 14008 14008
				14008 14008 14008 14008 14008 14008 14008 14008 14008 14008 14008 14008 14008 14008 14008 14008 14008 14008
				14008 14008 14008 14008 14008 14008 14008 14008 14008 14008 14008 14008 14008 14008 14008 14008 14008 14008
				14008 14008 14008 14008 14008 14008 14008 14008 14008 14008 14008 14008 14008 14008 14008 14008 14008 14008
				14008 14008 14008 14008 14008 14008 14008 14008 14008 14008 14008 14008 14008 14008 14008 14008 14008 14008
				14008 14008 14008 14008 14008 14008 14008 14008 14008 14008 14008 14008 14008 14008 14008 14008 14008 14008
				14008 14008 14008 14008 14008 14008 14008 14008 14008 14008 14008 14008 14008 14008 14008 14008 14008 14008
				14008 14008 14008 14008 14008 14008 14008 14008 14008 14008 14008 14008 14008 14008 14008 14008 14008 14008
				14008 14008 14008 14008 14008 14008 14008 14008 14008 14008 14008 14008 14008 14008 14008 14008 14008 14008
				14008 14008 14008 14008 14008 14008 14008 14008 14008 14008 14008 14008 14008 14008 14008 14008 14008 14008
				14008 14008 14008 14008 14008 14008 14008 14008 14008 14008 14008 14008 14008 14008 14008 14008 14008 14008
				14008 14008 14008 14008 14008 14008 14008 14008 14008 14008 14008 14008 14008 14008 14008 14008 14008 14008
				14008 14008 14008 14008 14008 14008 14008 14008 14008 14008 14008 14008 14008 14008 14008 14008 14008 14008
				14008 14008 14008 14008 14008 14008 14008 14008 14008 14008 14008 14008 14008 14008 14008 14008 14008 14008
				14008 14008 14008 14008 14008 14008 14008 14008 14008 14008 14008 14008 14008 14008 14008 14008 14008 14008
				14008 14008 14008 14008 14008 14008 14008 14008 14008 14008 14008 14008 14008 14008 14008 14008 14008 14008
				14008 14008 14008 14008 14008 14008 14008 14008 14008 14008 14008 14008 14008 14008 14008 14008 14008 14008
				14008 14008 14008 14008 14008 14008 14008 14008 14008 14008 14008 14008 14008 14008 14008 14008 14008 14008
				14008 14008 14008>;

			PS_Config_Lmt_Short_Rawdata_N = <
				10100 10100 10100 10100 10100 10100 10100 10100 10100 10100 10100 10100 10100 10100 10100 10100 10100 10100
				10100 10100 10100 10100 10100 10100 10100 10100 10100 10100 10100 10100 10100 10100 10100 10100 10100 10100
				10100 10100 10100 10100 10100 10100 10100 10100 10100 10100 10100 10100 10100 10100 10100 10100 10100 10100
				10100 10100 10100 10100 10100 10100 10100 10100 10100 10100 10100 10100 10100 10100 10100 10100 10100 10100
				10100 10100 10100 10100 10100 10100 10100 10100 10100 10100 10100 10100 10100 10100 10100 10100 10100 10100
				10100 10100 10100 10100 10100 10100 10100 10100 10100 10100 10100 10100 10100 10100 10100 10100 10100 10100
				10100 10100 10100 10100 10100 10100 10100 10100 10100 10100 10100 10100 10100 10100 10100 10100 10100 10100
				10100 10100 10100 10100 10100 10100 10100 10100 10100 10100 10100 10100 10100 10100 10100 10100 10100 10100
				10100 10100 10100 10100 10100 10100 10100 10100 10100 10100 10100 10100 10100 10100 10100 10100 10100 10100
				10100 10100 10100 10100 10100 10100 10100 10100 10100 10100 10100 10100 10100 10100 10100 10100 10100 10100
				10100 10100 10100 10100 10100 10100 10100 10100 10100 10100 10100 10100 10100 10100 10100 10100 10100 10100
				10100 10100 10100 10100 10100 10100 10100 10100 10100 10100 10100 10100 10100 10100 10100 10100 10100 10100
				10100 10100 10100 10100 10100 10100 10100 10100 10100 10100 10100 10100 10100 10100 10100 10100 10100 10100
				10100 10100 10100 10100 10100 10100 10100 10100 10100 10100 10100 10100 10100 10100 10100 10100 10100 10100
				10100 10100 10100 10100 10100 10100 10100 10100 10100 10100 10100 10100 10100 10100 10100 10100 10100 10100
				10100 10100 10100 10100 10100 10100 10100 10100 10100 10100 10100 10100 10100 10100 10100 10100 10100 10100
				10100 10100 10100 10100 10100 10100 10100 10100 10100 10100 10100 10100 10100 10100 10100 10100 10100 10100
				10100 10100 10100 10100 10100 10100 10100 10100 10100 10100 10100 10100 10100 10100 10100 10100 10100 10100
				10100 10100 10100 10100 10100 10100 10100 10100 10100 10100 10100 10100 10100 10100 10100 10100 10100 10100
				10100 10100 10100 10100 10100 10100 10100 10100 10100 10100 10100 10100 10100 10100 10100 10100 10100 10100
				10100 10100 10100 10100 10100 10100 10100 10100 10100 10100 10100 10100 10100 10100 10100 10100 10100 10100
				10100 10100 10100 10100 10100 10100 10100 10100 10100 10100 10100 10100 10100 10100 10100 10100 10100 10100
				10100 10100 10100 10100 10100 10100 10100 10100 10100 10100 10100 10100 10100 10100 10100 10100 10100 10100
				10100 10100 10100 10100 10100 10100 10100 10100 10100 10100 10100 10100 10100 10100 10100 10100 10100 10100
				10100 10100 10100 10100 10100 10100 10100 10100 10100 10100 10100 10100 10100 10100 10100 10100 10100 10100
				10100 10100 10100 10100 10100 10100 10100 10100 10100 10100 10100 10100 10100 10100 10100 10100 10100 10100
				10100 10100 10100 10100 10100 10100 10100 10100 10100 10100 10100 10100 10100 10100 10100 10100 10100 10100
				10100 10100 10100 10100 10100 10100 10100 10100 10100 10100 10100 10100 10100 10100 10100 10100 10100 10100
				10100 10100 10100 10100 10100 10100 10100 10100 10100 10100 10100 10100 10100 10100 10100 10100 10100 10100
				10100 10100 10100 10100 10100 10100 10100 10100 10100 10100 10100 10100 10100 10100 10100 10100 10100 10100
				10100 10100 10100 10100 10100 10100 10100 10100 10100 10100 10100 10100 10100 10100 10100 10100 10100 10100
				10100 10100 10100 10100 10100 10100 10100 10100 10100 10100 10100 10100 10100 10100 10100 10100 10100 10100
				10100 10100 10100>;

			PS_Config_Lmt_Open_Rawdata_P = <
				65535 2470 2429 2408 2353 2292 2260 65535 2009 2111 65535 2351 2374 2411 2436 2437 2482 65535
				2565 2523 2489 2468 2416 2369 2356 2309 2325 2440 2415 2451 2458 2491 2516 2517 2542 2506
				2640 2589 2562 2533 2481 2432 2407 2358 2370 2454 2429 2478 2486 2523 2547 2545 2566 2542
				2681 2625 2607 2577 2526 2475 2453 2400 2411 2471 2446 2499 2510 2544 2566 2568 2591 2569
				2712 2657 2635 2612 2562 2509 2489 2435 2449 2636 2614 2653 2675 2708 2726 2729 2751 2738
				2754 2698 2671 2649 2589 2533 2512 2450 2467 2608 2584 2629 2645 2675 2699 2705 2733 2734
				2827 2764 2737 2720 2667 2615 2603 2542 2566 2601 2586 2624 2640 2673 2689 2695 2717 2730
				2880 2818 2790 2768 2713 2657 2632 2575 2591 2688 2668 2706 2727 2761 2775 2778 2797 2815
				2953 2891 2866 2848 2800 2747 2720 2668 2681 2783 2754 2804 2813 2855 2877 2871 2898 2933
				3016 2950 2927 2894 2836 2787 2759 2703 2715 2705 2680 2724 2738 2771 2792 2796 2818 2863
				3063 2996 2971 2941 2888 2838 2813 2758 2766 2825 2792 2839 2859 2895 2923 2918 2943 3002
				3125 3058 3044 3011 2954 2895 2873 2814 2827 2834 2804 2856 2874 2911 2939 2944 2962 3025
				3177 3104 3077 3056 2990 2932 2912 2843 2866 2919 2901 2939 2964 2993 3013 3017 3037 3100
				3161 3088 3066 3041 2985 2929 2901 2843 2857 2936 2918 2955 2981 3010 3025 3032 3048 3119
				3333 3259 3233 3210 3150 3090 3065 3002 3017 2939 2920 2968 2982 3010 3035 3034 3055 3135
				3389 3321 3297 3263 3207 3143 3115 3059 3070 3119 3102 3143 3164 3195 3219 3224 3242 3315
				3433 3356 3339 3308 3261 3205 3174 3122 3122 3182 3158 3212 3230 3268 3293 3287 3304 3382
				3478 3402 3387 3346 3284 3227 3200 3143 3154 3164 3140 3189 3210 3249 3277 3280 3301 3374
				3647 3562 3549 3522 3462 3406 3381 3325 3332 3324 3307 3352 3377 3417 3437 3448 3464 3543
				3618 3548 3534 3497 3434 3378 3350 3290 3301 3403 3385 3431 3452 3489 3514 3525 3542 3612
				3713 3639 3613 3583 3525 3464 3434 3375 3388 3419 3405 3444 3462 3492 3517 3528 3548 3630
				3795 3728 3706 3671 3604 3548 3518 3459 3471 3473 3455 3497 3517 3548 3574 3585 3604 3683
				3865 3809 3783 3748 3689 3633 3597 3541 3549 3541 3518 3564 3580 3618 3653 3653 3671 3748
				3905 3863 3849 3805 3752 3693 3657 3598 3608 3584 3564 3609 3630 3664 3688 3700 3714 3793
				4040 4012 3994 3955 3889 3832 3804 3749 3753 3655 3639 3682 3711 3752 3770 3783 3794 3867
				4109 4089 4078 4036 3970 3914 3886 3823 3830 3753 3735 3781 3804 3840 3865 3879 3893 3963
				4101 4099 4074 4042 3976 3917 3893 3826 3836 3830 3816 3847 3885 3907 3933 3954 3970 4038
				3935 4273 4246 4206 4143 4080 4049 3987 3994 3857 3843 3885 3919 3954 3982 3998 4011 3770
				3994 4361 4347 4313 4256 4197 4155 4098 4098 3927 3914 3959 3980 4018 4047 4054 4067 3802
				3937 4351 4327 4285 4225 4172 4129 4074 4067 3977 3976 4019 4053 4085 4116 4134 4152 3863
				4033 4528 4507 4460 4411 4357 4312 4266 4253 4115 4099 4148 4172 4206 4235 4242 4264 3903
				4290 4351 4612 4567 4495 4435 4396 4340 4330 4157 4148 4196 4225 4260 4295 4302 4081 4126
				5120 5120 5120>;

			PS_Config_Lmt_Open_Rawdata_N = <
				(-65535) 1058 1041 1032 1009 982 968 (-65535) 861 905 (-65535) 1007 1018 1033 1044 1045 1064 (-65535)
				1099 1081 1067 1058 1036 1015 1010 989 997 1046 1035 1051 1054 1067 1078 1079 1090 1074
				1132 1109 1098 1085 1063 1042 1031 1010 1016 1052 1041 1062 1066 1081 1091 1091 1100 1090
				1149 1125 1117 1105 1082 1061 1051 1028 1033 1059 1048 1071 1076 1090 1100 1100 1111 1101
				1162 1139 1129 1120 1098 1075 1067 1043 1049 1130 1120 1137 1147 1160 1168 1169 1179 1174
				1180 1156 1145 1135 1109 1085 1076 1050 1057 1118 1108 1127 1133 1147 1157 1159 1171 1172
				1211 1184 1173 1166 1143 1121 1115 1090 1100 1115 1108 1124 1132 1145 1153 1155 1165 1170
				1234 1208 1196 1186 1163 1139 1128 1103 1111 1152 1144 1160 1169 1183 1189 1190 1199 1207
				1265 1239 1228 1220 1200 1177 1166 1144 1149 1193 1180 1202 1205 1223 1233 1231 1242 1257
				1292 1264 1255 1240 1216 1195 1183 1159 1163 1159 1148 1168 1174 1187 1196 1198 1208 1227
				1313 1284 1273 1261 1238 1216 1205 1182 1186 1211 1196 1217 1225 1241 1253 1250 1261 1286
				1339 1310 1304 1291 1266 1241 1231 1206 1211 1214 1202 1224 1232 1247 1259 1262 1270 1297
				1361 1330 1319 1310 1282 1256 1248 1219 1228 1251 1243 1259 1270 1283 1291 1293 1301 1328
				1355 1324 1314 1303 1279 1255 1243 1219 1225 1258 1250 1267 1277 1290 1297 1300 1306 1337
				1429 1397 1385 1376 1350 1324 1313 1286 1293 1259 1252 1272 1278 1290 1301 1300 1309 1343
				1453 1423 1413 1399 1375 1347 1335 1311 1316 1337 1330 1347 1356 1369 1379 1382 1390 1421
				1471 1438 1431 1418 1397 1373 1360 1338 1338 1364 1354 1376 1384 1400 1411 1409 1416 1450
				1490 1458 1451 1434 1408 1383 1372 1347 1352 1356 1346 1367 1376 1393 1405 1406 1415 1446
				1563 1526 1521 1510 1484 1460 1449 1425 1428 1424 1417 1436 1447 1465 1473 1478 1484 1519
				1550 1520 1514 1499 1472 1448 1436 1410 1415 1459 1451 1471 1480 1495 1506 1511 1518 1548
				1591 1559 1549 1535 1511 1484 1472 1447 1452 1465 1459 1476 1484 1496 1507 1512 1520 1556
				1627 1598 1588 1573 1544 1520 1508 1483 1487 1489 1481 1499 1507 1520 1532 1537 1544 1579
				1657 1633 1621 1606 1581 1557 1541 1517 1521 1517 1508 1528 1534 1550 1565 1565 1573 1606
				1673 1655 1649 1631 1608 1583 1567 1542 1546 1536 1528 1547 1556 1570 1580 1586 1592 1625
				1732 1720 1712 1695 1667 1642 1630 1607 1609 1567 1559 1578 1591 1608 1616 1621 1626 1657
				1761 1753 1748 1730 1702 1678 1666 1639 1642 1609 1601 1621 1630 1646 1657 1663 1669 1699
				1757 1757 1746 1732 1704 1679 1669 1640 1644 1642 1636 1649 1665 1675 1685 1694 1702 1730
				1687 1831 1820 1802 1775 1748 1735 1709 1712 1653 1647 1665 1679 1694 1706 1714 1719 1616
				1712 1869 1863 1849 1824 1799 1781 1756 1756 1683 1678 1697 1706 1722 1735 1738 1743 1630
				1687 1865 1855 1837 1811 1788 1769 1746 1743 1705 1704 1723 1737 1751 1764 1772 1780 1655
				1729 1940 1931 1912 1891 1867 1848 1828 1823 1763 1757 1778 1788 1802 1815 1818 1828 1673
				1838 1865 1976 1957 1927 1901 1884 1860 1856 1781 1778 1798 1811 1826 1841 1844 1749 1768
				(-511) (-511) (-511)>;

			PS_Config_Lmt_FW_Rawdata_P = <
				65535 1110 1100 1121 1110 1127 1106 65535 1130 1113 65535 1100 1117 1126 1112 1106 1130 65535
				1130 1112 1141 1151 1092 1137 1088 1144 1148 1119 1134 1112 1121 1119 1123 1119 1117 1123
				1119 1124 1100 1127 1120 1126 1123 1105 1126 1113 1142 1110 1121 1140 1112 1107 1135 1098
				1137 1120 1124 1126 1100 1119 1112 1110 1119 1105 1120 1133 1106 1124 1123 1113 1130 1110
				1131 1120 1126 1134 1109 1128 1093 1133 1134 1109 1128 1121 1092 1140 1102 1099 1121 1095
				1126 1128 1089 1121 1116 1100 1145 1095 1119 1109 1116 1127 1106 1128 1116 1123 1119 1124
				1112 1119 1116 1120 1128 1109 1126 1100 1126 1123 1109 1120 1112 1135 1114 1105 1135 1113
				1134 1138 1093 1114 1134 1082 1138 1123 1098 1131 1103 1131 1119 1117 1120 1099 1142 1102
				1098 1126 1135 1110 1127 1116 1103 1119 1144 1093 1138 1130 1092 1141 1103 1137 1114 1088
				1148 1123 1112 1134 1105 1127 1103 1121 1138 1126 1126 1107 1127 1106 1130 1109 1123 1137
				1099 1130 1128 1095 1134 1100 1134 1110 1112 1084 1158 1096 1123 1138 1096 1135 1109 1119
				1127 1117 1103 1137 1092 1134 1102 1113 1131 1128 1123 1123 1126 1121 1119 1109 1128 1126
				1126 1116 1114 1131 1114 1130 1110 1109 1126 1130 1126 1117 1123 1116 1112 1140 1106 1099
				1086 1078 1130 1109 1127 1124 1120 1102 1151 1120 1126 1096 1133 1109 1135 1085 1142 1119
				1128 1121 1126 1119 1120 1112 1121 1107 1131 1105 1124 1135 1113 1112 1117 1135 1123 1088
				1110 1105 1133 1110 1126 1116 1124 1119 1120 1116 1110 1120 1124 1119 1121 1121 1128 1120
				1128 1131 1119 1117 1113 1123 1114 1127 1119 1126 1099 1144 1099 1134 1099 1133 1103 1113
				1119 1119 1103 1142 1098 1145 1098 1144 1106 1110 1119 1133 1123 1133 1119 1116 1116 1107
				1092 1124 1130 1113 1114 1134 1105 1128 1098 1137 1098 1140 1099 1147 1105 1113 1133 1138
				1107 1123 1107 1134 1123 1099 1124 1128 1109 1116 1120 1120 1137 1096 1128 1138 1106 1098
				1107 1082 1148 1114 1117 1121 1116 1110 1096 1110 1135 1095 1152 1096 1135 1120 1106 1113
				1121 1105 1113 1116 1112 1138 1119 1126 1105 1133 1124 1116 1127 1102 1149 1100 1117 1109
				1119 1114 1124 1107 1130 1114 1114 1119 1107 1124 1124 1121 1099 1140 1106 1106 1116 1100
				1159 1100 1128 1123 1124 1133 1093 1130 1110 1113 1107 1141 1093 1137 1093 1106 1120 1134
				1110 1133 1110 1138 1095 1133 1120 1126 1099 1130 1126 1117 1106 1131 1114 1086 1145 1117
				1119 1126 1131 1120 1099 1131 1110 1128 1128 1091 1102 1135 1110 1117 1096 1123 1128 1110
				1123 1137 1123 1134 1095 1117 1126 1124 1126 1109 1100 1126 1112 1109 1141 1123 1096 1114
				1102 1137 1119 1117 1124 1112 1130 1116 1116 1128 1099 1113 1116 1110 1123 1113 1112 1130
				1113 1120 1138 1128 1107 1138 1114 1124 1130 1113 1109 1103 1151 1106 1112 1116 1127 1107
				1117 1116 1135 1113 1100 1149 1120 1110 1123 1154 1158 1093 1116 1144 1117 1105 1126 1100
				1137 1128 1079 1081 1148 1124 1107 1117 1124 1133 1124 1140 1098 1099 1144 1134 1120 1123
				1103 1100 1095 1078 1128 1144 1119 1110 1110 1134 1131 1126 1112 1147 1107 1102 1114 1128
				3840 3840 3840>;

			PS_Config_Lmt_FW_Rawdata_N = <
				(-65535) 476 472 481 476 483 474 (-65535) 484 477 (-65535) 472 479 482 476 474 484 (-65535)
				484 476 489 493 468 487 466 490 492 479 486 476 481 479 481 479 479 481
				479 482 472 483 480 482 481 473 482 477 490 476 481 488 476 475 487 470
				487 480 482 482 472 479 476 476 479 473 480 485 474 482 481 477 484 476
				485 480 482 486 475 484 469 485 486 475 484 481 468 488 472 471 481 469
				482 484 467 481 478 472 491 469 479 475 478 483 474 484 478 481 479 482
				476 479 478 480 484 475 482 472 482 481 475 480 476 487 478 473 487 477
				486 488 469 478 486 464 488 481 470 485 473 485 479 479 480 471 490 472
				470 482 487 476 483 478 473 479 490 469 488 484 468 489 473 487 478 466
				492 481 476 486 473 483 473 481 488 482 482 475 483 474 484 475 481 487
				471 484 484 469 486 472 486 476 476 464 496 470 481 488 470 487 475 479
				483 479 473 487 468 486 472 477 485 484 481 481 482 481 479 475 484 482
				482 478 478 485 478 484 476 475 482 484 482 479 481 478 476 488 474 471
				466 462 484 475 483 482 480 472 493 480 482 470 485 475 487 465 490 479
				484 481 482 479 480 476 481 475 485 473 482 487 477 476 479 487 481 466
				476 473 485 476 482 478 482 479 480 478 476 480 482 479 481 481 484 480
				484 485 479 479 477 481 478 483 479 482 471 490 471 486 471 485 473 477
				479 479 473 490 470 491 470 490 474 476 479 485 481 485 479 478 478 475
				468 482 484 477 478 486 473 484 470 487 470 488 471 491 473 477 485 488
				475 481 475 486 481 471 482 484 475 478 480 480 487 470 484 488 474 470
				475 464 492 478 479 481 478 476 470 476 487 469 494 470 487 480 474 477
				481 473 477 478 476 488 479 482 473 485 482 478 483 472 493 472 479 475
				479 478 482 475 484 478 478 479 475 482 482 481 471 488 474 474 478 472
				497 472 484 481 482 485 469 484 476 477 475 489 469 487 469 474 480 486
				476 485 476 488 469 485 480 482 471 484 482 479 474 485 478 466 491 479
				479 482 485 480 471 485 476 484 484 467 472 487 476 479 470 481 484 476
				481 487 481 486 469 479 482 482 482 475 472 482 476 475 489 481 470 478
				472 487 479 479 482 476 484 478 478 484 471 477 478 476 481 477 476 484
				477 480 488 484 475 488 478 482 484 477 475 473 493 474 476 478 483 475
				479 478 487 477 472 493 480 476 481 494 496 469 478 490 479 473 482 472
				487 484 463 463 492 482 475 479 482 485 482 488 470 471 490 486 480 481
				473 472 469 462 484 490 479 476 476 486 485 482 476 491 475 472 478 484
				240 240 240>;

			PS_Config_Lmt_FW_CC_P = <
				65535 29 29 28 26 25 25 65535 22 22 65535 25 26 26 28 29 29 65535
				30 29 29 28 26 26 25 23 23 23 25 25 26 26 28 29 29 30
				30 29 29 28 26 26 25 23 23 23 23 25 26 26 28 29 29 30
				30 29 29 28 26 25 25 23 23 23 25 25 26 26 28 29 29 30
				30 29 29 28 26 26 25 25 23 23 25 25 26 28 28 29 29 30
				30 29 29 28 26 26 25 25 23 23 25 25 26 26 28 29 29 30
				30 29 29 28 26 26 25 25 23 23 25 26 26 28 28 29 30 30
				30 29 29 28 26 26 25 23 23 23 25 25 26 26 28 29 29 30
				30 29 29 28 26 26 25 25 23 23 25 25 26 26 28 29 29 30
				30 29 28 28 26 26 25 25 23 23 25 25 26 28 28 29 29 30
				30 29 29 28 28 26 26 25 23 23 25 26 26 28 28 29 29 30
				30 29 28 28 26 26 25 25 23 23 25 26 26 28 28 29 29 30
				30 29 29 28 28 26 26 25 23 25 25 26 28 28 29 29 30 30
				30 29 29 28 28 26 26 25 23 23 25 26 26 28 28 29 29 30
				30 29 29 28 28 26 26 25 25 25 25 26 26 28 28 29 29 30
				30 29 29 28 28 26 26 25 25 25 25 26 28 28 29 29 30 30
				32 30 29 29 28 28 26 26 25 25 26 26 28 28 29 29 30 32
				32 30 29 29 28 28 26 26 25 25 26 26 28 28 29 29 30 32
				32 30 30 29 29 28 28 26 26 26 26 28 28 29 29 30 30 32
				32 30 30 29 29 28 28 26 26 26 26 28 28 29 29 30 30 32
				32 30 30 30 29 29 28 28 26 28 28 29 29 29 30 30 32 32
				32 32 30 30 29 29 28 28 28 28 28 29 29 29 30 30 32 32
				33 32 32 32 30 30 29 29 28 28 28 29 29 29 30 30 32 33
				33 32 32 30 30 29 29 28 28 28 28 29 29 30 30 30 32 32
				33 32 32 32 30 30 30 29 29 28 28 29 30 30 30 32 32 33
				33 33 32 32 32 30 30 29 29 29 29 30 30 32 32 32 33 33
				34 33 33 33 32 32 30 30 30 29 30 30 30 32 32 32 33 33
				36 33 33 33 32 32 32 30 30 30 30 30 32 32 32 32 33 34
				36 33 33 33 33 32 32 30 30 30 30 32 32 32 33 33 33 36
				36 34 33 33 33 32 32 32 32 30 30 32 32 32 33 33 33 36
				36 34 34 34 33 33 33 32 32 32 32 32 33 33 33 33 34 36
				36 36 34 34 33 33 33 33 33 32 32 33 33 33 33 34 36 36
				314 314 314>;

			PS_Config_Lmt_FW_CC_N = <
				(-65535) 13 13 12 12 11 11 (-65535) 10 10 (-65535) 11 12 12 12 13 13 (-65535)
				14 13 13 12 12 12 11 11 11 11 11 11 12 12 12 13 13 14
				14 13 13 12 12 12 11 11 11 11 11 11 12 12 12 13 13 14
				14 13 13 12 12 11 11 11 11 11 11 11 12 12 12 13 13 14
				14 13 13 12 12 12 11 11 11 11 11 11 12 12 12 13 13 14
				14 13 13 12 12 12 11 11 11 11 11 11 12 12 12 13 13 14
				14 13 13 12 12 12 11 11 11 11 11 12 12 12 12 13 14 14
				14 13 13 12 12 12 11 11 11 11 11 11 12 12 12 13 13 14
				14 13 13 12 12 12 11 11 11 11 11 11 12 12 12 13 13 14
				14 13 12 12 12 12 11 11 11 11 11 11 12 12 12 13 13 14
				14 13 13 12 12 12 12 11 11 11 11 12 12 12 12 13 13 14
				14 13 12 12 12 12 11 11 11 11 11 12 12 12 12 13 13 14
				14 13 13 12 12 12 12 11 11 11 11 12 12 12 13 13 14 14
				14 13 13 12 12 12 12 11 11 11 11 12 12 12 12 13 13 14
				14 13 13 12 12 12 12 11 11 11 11 12 12 12 12 13 13 14
				14 13 13 12 12 12 12 11 11 11 11 12 12 12 13 13 14 14
				14 14 13 13 12 12 12 12 11 11 12 12 12 12 13 13 14 14
				14 14 13 13 12 12 12 12 11 11 12 12 12 12 13 13 14 14
				14 14 14 13 13 12 12 12 12 12 12 12 12 13 13 14 14 14
				14 14 14 13 13 12 12 12 12 12 12 12 12 13 13 14 14 14
				14 14 14 14 13 13 12 12 12 12 12 13 13 13 14 14 14 14
				14 14 14 14 13 13 12 12 12 12 12 13 13 13 14 14 14 14
				15 14 14 14 14 14 13 13 12 12 12 13 13 13 14 14 14 15
				15 14 14 14 14 13 13 12 12 12 12 13 13 14 14 14 14 14
				15 14 14 14 14 14 14 13 13 12 12 13 14 14 14 14 14 15
				15 15 14 14 14 14 14 13 13 13 13 14 14 14 14 14 15 15
				16 15 15 15 14 14 14 14 14 13 14 14 14 14 14 14 15 15
				16 15 15 15 14 14 14 14 14 14 14 14 14 14 14 14 15 16
				16 15 15 15 15 14 14 14 14 14 14 14 14 14 15 15 15 16
				16 16 15 15 15 14 14 14 14 14 14 14 14 14 15 15 15 16
				16 16 16 16 15 15 15 14 14 14 14 14 15 15 15 15 16 16
				16 16 16 16 15 15 15 15 15 14 14 15 15 15 15 16 16 16
				0 0 0>;

			PS_Config_Lmt_FW_Diff_P = <
				65535 50 50 50 50 50 50 65535 50 50 65535 50 50 50 50 50 50 65535
				50 50 50 50 50 50 50 50 50 50 50 50 50 50 50 50 50 50
				50 50 50 50 50 50 50 50 50 50 50 50 50 50 50 50 50 50
				50 50 50 50 50 50 50 50 50 50 50 50 50 50 50 50 50 50
				50 50 50 50 50 50 50 50 50 50 50 50 50 50 50 50 50 50
				50 50 50 50 50 50 50 50 50 50 50 50 50 50 50 50 50 50
				50 50 50 50 50 50 50 50 50 50 50 50 50 50 50 50 50 50
				50 50 50 50 50 50 50 50 50 50 50 50 50 50 50 50 50 50
				50 50 50 50 50 50 50 50 50 50 50 50 50 50 50 50 50 50
				50 50 50 50 50 50 50 50 50 50 50 50 50 50 50 50 50 50
				50 50 50 50 50 50 50 50 50 50 50 50 50 50 50 50 50 50
				50 50 50 50 50 50 50 50 50 50 50 50 50 50 50 50 50 50
				50 50 50 50 50 50 50 50 50 50 50 50 50 50 50 50 50 50
				50 50 50 50 50 50 50 50 50 50 50 50 50 50 50 50 50 50
				50 50 50 50 50 50 50 50 50 50 50 50 50 50 50 50 50 50
				50 50 50 50 50 50 50 50 50 50 50 50 50 50 50 50 50 50
				50 50 50 50 50 50 50 50 50 50 50 50 50 50 50 50 50 50
				50 50 50 50 50 50 50 50 50 50 50 50 50 50 50 50 50 50
				50 50 50 50 50 50 50 50 50 50 50 50 50 50 50 50 50 50
				50 50 50 50 50 50 50 50 50 50 50 50 50 50 50 50 50 50
				50 50 50 50 50 50 50 50 50 50 50 50 50 50 50 50 50 50
				50 50 50 50 50 50 50 50 50 50 50 50 50 50 50 50 50 50
				50 50 50 50 50 50 50 50 50 50 50 50 50 50 50 50 50 50
				50 50 50 50 50 50 50 50 50 50 50 50 50 50 50 50 50 50
				50 50 50 50 50 50 50 50 50 50 50 50 50 50 50 50 50 50
				50 50 50 50 50 50 50 50 50 50 50 50 50 50 50 50 50 50
				50 50 50 50 50 50 50 50 50 50 50 50 50 50 50 50 50 50
				50 50 50 50 50 50 50 50 50 50 50 50 50 50 50 50 50 50
				50 50 50 50 50 50 50 50 50 50 50 50 50 50 50 50 50 50
				50 50 50 50 50 50 50 50 50 50 50 50 50 50 50 50 50 50
				50 50 50 50 50 50 50 50 50 50 50 50 50 50 50 50 50 50
				50 50 50 50 50 50 50 50 50 50 50 50 50 50 50 50 50 50
				75 75 75>;

			PS_Config_Lmt_FW_Diff_N = <
				(-65535) (-50) (-50) (-50) (-50) (-50) (-50) (-65535) (-50) (-50) (-65535) (-50) (-50) (-50) (-50) (-50) (-50) (-65535)
				(-50) (-50) (-50) (-50) (-50) (-50) (-50) (-50) (-50) (-50) (-50) (-50) (-50) (-50) (-50) (-50) (-50) (-50)
				(-50) (-50) (-50) (-50) (-50) (-50) (-50) (-50) (-50) (-50) (-50) (-50) (-50) (-50) (-50) (-50) (-50) (-50)
				(-50) (-50) (-50) (-50) (-50) (-50) (-50) (-50) (-50) (-50) (-50) (-50) (-50) (-50) (-50) (-50) (-50) (-50)
				(-50) (-50) (-50) (-50) (-50) (-50) (-50) (-50) (-50) (-50) (-50) (-50) (-50) (-50) (-50) (-50) (-50) (-50)
				(-50) (-50) (-50) (-50) (-50) (-50) (-50) (-50) (-50) (-50) (-50) (-50) (-50) (-50) (-50) (-50) (-50) (-50)
				(-50) (-50) (-50) (-50) (-50) (-50) (-50) (-50) (-50) (-50) (-50) (-50) (-50) (-50) (-50) (-50) (-50) (-50)
				(-50) (-50) (-50) (-50) (-50) (-50) (-50) (-50) (-50) (-50) (-50) (-50) (-50) (-50) (-50) (-50) (-50) (-50)
				(-50) (-50) (-50) (-50) (-50) (-50) (-50) (-50) (-50) (-50) (-50) (-50) (-50) (-50) (-50) (-50) (-50) (-50)
				(-50) (-50) (-50) (-50) (-50) (-50) (-50) (-50) (-50) (-50) (-50) (-50) (-50) (-50) (-50) (-50) (-50) (-50)
				(-50) (-50) (-50) (-50) (-50) (-50) (-50) (-50) (-50) (-50) (-50) (-50) (-50) (-50) (-50) (-50) (-50) (-50)
				(-50) (-50) (-50) (-50) (-50) (-50) (-50) (-50) (-50) (-50) (-50) (-50) (-50) (-50) (-50) (-50) (-50) (-50)
				(-50) (-50) (-50) (-50) (-50) (-50) (-50) (-50) (-50) (-50) (-50) (-50) (-50) (-50) (-50) (-50) (-50) (-50)
				(-50) (-50) (-50) (-50) (-50) (-50) (-50) (-50) (-50) (-50) (-50) (-50) (-50) (-50) (-50) (-50) (-50) (-50)
				(-50) (-50) (-50) (-50) (-50) (-50) (-50) (-50) (-50) (-50) (-50) (-50) (-50) (-50) (-50) (-50) (-50) (-50)
				(-50) (-50) (-50) (-50) (-50) (-50) (-50) (-50) (-50) (-50) (-50) (-50) (-50) (-50) (-50) (-50) (-50) (-50)
				(-50) (-50) (-50) (-50) (-50) (-50) (-50) (-50) (-50) (-50) (-50) (-50) (-50) (-50) (-50) (-50) (-50) (-50)
				(-50) (-50) (-50) (-50) (-50) (-50) (-50) (-50) (-50) (-50) (-50) (-50) (-50) (-50) (-50) (-50) (-50) (-50)
				(-50) (-50) (-50) (-50) (-50) (-50) (-50) (-50) (-50) (-50) (-50) (-50) (-50) (-50) (-50) (-50) (-50) (-50)
				(-50) (-50) (-50) (-50) (-50) (-50) (-50) (-50) (-50) (-50) (-50) (-50) (-50) (-50) (-50) (-50) (-50) (-50)
				(-50) (-50) (-50) (-50) (-50) (-50) (-50) (-50) (-50) (-50) (-50) (-50) (-50) (-50) (-50) (-50) (-50) (-50)
				(-50) (-50) (-50) (-50) (-50) (-50) (-50) (-50) (-50) (-50) (-50) (-50) (-50) (-50) (-50) (-50) (-50) (-50)
				(-50) (-50) (-50) (-50) (-50) (-50) (-50) (-50) (-50) (-50) (-50) (-50) (-50) (-50) (-50) (-50) (-50) (-50)
				(-50) (-50) (-50) (-50) (-50) (-50) (-50) (-50) (-50) (-50) (-50) (-50) (-50) (-50) (-50) (-50) (-50) (-50)
				(-50) (-50) (-50) (-50) (-50) (-50) (-50) (-50) (-50) (-50) (-50) (-50) (-50) (-50) (-50) (-50) (-50) (-50)
				(-50) (-50) (-50) (-50) (-50) (-50) (-50) (-50) (-50) (-50) (-50) (-50) (-50) (-50) (-50) (-50) (-50) (-50)
				(-50) (-50) (-50) (-50) (-50) (-50) (-50) (-50) (-50) (-50) (-50) (-50) (-50) (-50) (-50) (-50) (-50) (-50)
				(-50) (-50) (-50) (-50) (-50) (-50) (-50) (-50) (-50) (-50) (-50) (-50) (-50) (-50) (-50) (-50) (-50) (-50)
				(-50) (-50) (-50) (-50) (-50) (-50) (-50) (-50) (-50) (-50) (-50) (-50) (-50) (-50) (-50) (-50) (-50) (-50)
				(-50) (-50) (-50) (-50) (-50) (-50) (-50) (-50) (-50) (-50) (-50) (-50) (-50) (-50) (-50) (-50) (-50) (-50)
				(-50) (-50) (-50) (-50) (-50) (-50) (-50) (-50) (-50) (-50) (-50) (-50) (-50) (-50) (-50) (-50) (-50) (-50)
				(-50) (-50) (-50) (-50) (-50) (-50) (-50) (-50) (-50) (-50) (-50) (-50) (-50) (-50) (-50) (-50) (-50) (-50)
				(-75) (-75) (-75)>;

			PS_Config_Diff_Test_Frame = <50>;
		};
	};
};
